# Polarfire SoC register map
Vendor: Microchip; File version: 1.0
CPU: Microchip PolarFire SoC 1.0, little endian
Registers are 32-bit, read-write, reset 0x0 unless marked. A register's access mark holds for its fields unless they carry their own. Offsets are from the block's base; [hi:lo] are bit positions; {n}, {i} and the like mark numbered series; 'fields as' and 'values as' point back to an identical list; <NAME> marks a mode.

## SCB_REGS — SCB_REGS Controller
Base 0x20003000
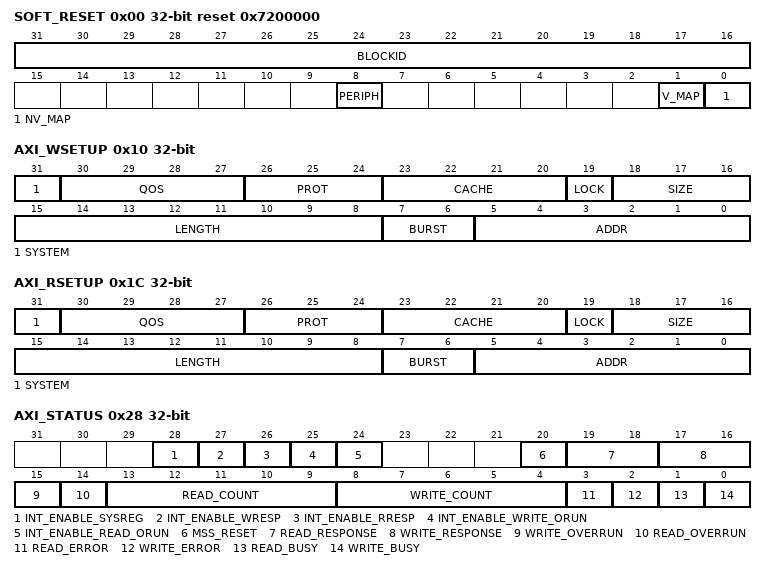
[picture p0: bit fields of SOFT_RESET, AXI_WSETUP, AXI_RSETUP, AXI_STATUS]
0x00 SOFT_RESET reset 0x7200000 — System Reset Register. This MSS soft reset register is not readable or writeable by the MSS or user or DRI.
  [31:16] BLOCKID ro — This returns the block type and chip location.
  [8] PERIPH — This asserts the functional reset of the block. It is asserted at power up, the bit self clears i.e. is similar to a W1P bit. This bit is activated global_periph_reset
  [1] V_MAP — This when asserted resets all the register bits apart from the non-volatile registers, the bit self clears i.e. is similar to a W1P bit. This bit is activated global_map_reset.
  [0] NV_MAP — This when asserted resets all the non-volatile register bits e.g. RW-P bits, the bit self clears i.e. is similar to a W1P bit. This bit is activated global_map_reset.
0x10 AXI_WSETUP — Axi Write Setup. Not accesible from MSS or user or DRI.
  [31] SYSTEM — 0: AXI transaction uses ID 0 and passes through MPU block 1: AXI transaction uses ID 1 and bypasses the MPU block
  [30:27] QOS — Sets the AXI QOS value, higher values have higher priority in the switch
  [26:24] PROT — Sets the AXI protection value
  [23:20] CACHE — Sets the AXI Cache value
  [19] LOCK — Sets the AXI lock
  [18:16] SIZE — Set the AXI size (width)
  [15:8] LENGTH — Sets the AXI burst length
  [7:6] BURST — Sets the AXi burst type
  [5:0] ADDR — Sets the upper 6-bits of the address bus
0x14 AXI_WADDR — AXI Write Address. Not accesible from MSS or user or DRI.
  [31:0] ADDR — This sets the AXI write address. A write to this register triggers the AXI AW cycle
0x18 AXI_WDATA — AXI Write Data. This is write only register, reads will return zero. Not accesible from MSS or user or DRI.
  [31:0] DATA — Write Data, when written will initiate a AHB write transfer through the write data FIFO.Data must be written using word operations. If AWSIZE<=2 then a AXI Write data cycle will be started every cycle, if AWSIZE=3 a AXI Write data cycle will be started every other cycle.
0x1C AXI_RSETUP — AXI Read Setup. Not accesible from MSS or user or DRI.
  fields as AXI_WSETUP
0x20 AXI_RADDR — AXI Read Address. Not accesible from MSS or user or DRI.
  [31:0] ADDR — This sets the AXI read address. A write to this register triggers the AXI AR cycle
0x24 AXI_RDATA — AHB Read data. This is a read only register, writes will be have no effect.
  [31:0] DATA — Read data from the AXI read FIFO
0x28 AXI_STATUS — AXI Master Status. Not accessible from MSS or user or DRI. This register provides status information and writes only supported on bits 28:24
  [28] INT_ENABLE_SYSREG — Enable SCB interrupt from the SCB Interrupt register
  [27] INT_ENABLE_WRESP — Enable SCB interrupt on write response error
  [26] INT_ENABLE_RRESP — Enable SCB interrupt on read response error
  [25] INT_ENABLE_WRITE_ORUN — Enable SCB interrupt on write overrun
  [24] INT_ENABLE_READ_ORUN — Enable SCB interrupt on read overrun
  [20] MSS_RESET — Indicates that the MSS has been reset and the SCB transfer may have failed. Is the internal MSS sticky_reset signal
  [19:18] READ_RESPONSE — Indicates the read response. When a non-zero value is detected the register will hold the value until the read_error bit is cleared or abort asserted
  [17:16] WRITE_RESPONSE — Indicates the write response. When a non-zero value is detected the register will hold the value until the write_error bit is cleared or abort asserted
  [15] WRITE_OVERRUN — Indicates the SCB bus wrote the write FIFO when empty. Is cleared by writing a ‘1’
  [14] READ_OVERRUN — Indicates the SCB bus read the read FIFO when empty. Is cleared by writing a ‘1’
  [13:9] READ_COUNT — Indicates how many 32-bit words are stored in the read FIFO
  [8:4] WRITE_COUNT — Indicates how many 32-bit words are stored in the write FIFO
  [3] READ_ERROR — Set when a read error response is received. Is cleared by writing a ‘1’
  [2] WRITE_ERROR — Set when a write error response is received. Is cleared by writing a ‘1’
  [1] READ_BUSY — Set during arvalid cycle and cleared on the last read response
  [0] WRITE_BUSY — Set during awvalid cycle and cleared on the write response
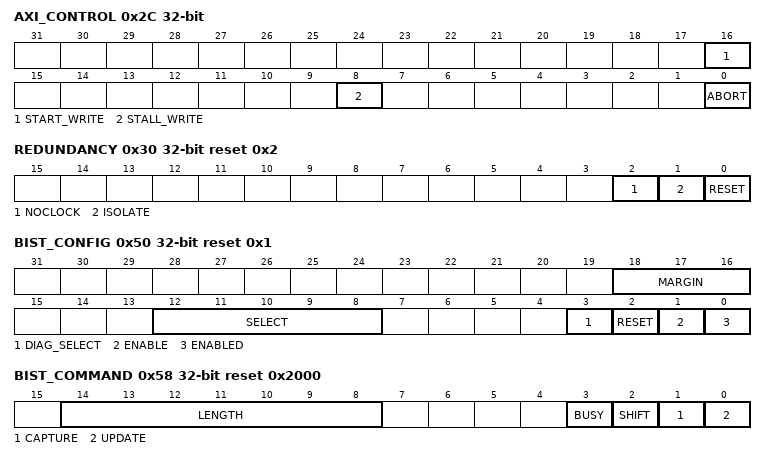
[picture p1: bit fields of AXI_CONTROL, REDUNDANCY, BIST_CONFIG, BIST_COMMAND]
0x2C AXI_CONTROL — AXI Cycle Controls. Not accesible from MSS or user or DRI.
  [16] START_WRITE — Starts AXI transfer when STALL_WRITE is set, reads as zero
  [8] STALL_WRITE — When set prevents the logic initiating AW cycle automatically. Write is started by START_WRITE. Allows up to 16 words (32-bits) of data to be queued allowing AXI to run more efficiently.
  [0] ABORT — Abort current transfer and reset the FSMS. May cause AXI protocol violations
0x30 REDUNDANCY reset 0x2 — Used to program MSS RAM redundancy system during system startup
  [2] NOCLOCK — When set stops the SCB clock creating the Redundancy clock. To allow for large recovery times on the redundancy ISOLATE and RESET inputs this bit should be set prior to toggling the reset/isolate bits and cleared afterwards.
  [1] ISOLATE — Asserts the Redundacy isolate, interface isolated when 1 (can be accessed by MSS in factory mode)
  [0] RESET — Asserts the Redundacy reset (can be accessed by MSS in factory mode)
0x50 BIST_CONFIG reset 0x1 — Used to access the BIST systems
  [18:16] MARGIN — Set the BIST memory margin, factory mode only
  [12:8] SELECT — Select the BIST engine 0-15
  [3] DIAG_SELECT — Assert the DIAG select
  [2] RESET — Assert the BIST reset
  [1] ENABLE — Enable the CPU BIST system
  [0] ENABLED ro — Indicates that CPU may use BIST system, UFS bit may disable this interface, available when factory mode set
0x54 BIST_DATA — Data value to be shifted into BIST system
  [31:0] DATA — Writes sets the data value to shifted, LSB shifted out first. Reads returns the shifted in value, MSB is last bit shifted in.
0x58 BIST_COMMAND reset 0x2000 — BIST Shift Controls
  [14:8] LENGTH — Number of bits to shift 1-127. If set to >32 the outgoing shift data for bits 33 upwards will be zero. This allows MBIST with CSR registers greater than 32 to be started with valid data loaded into bits 23:0 off the CSR register as specified in the data register. When >32 incoming data is not captured in the shift register, if the read data is to extracted then each shift operation should be <=32 bits. To read a 88 bit register will require 3 shift operatiosn of 32, 32 and 24 bits
  [3] BUSY ro — Indicates that the shift is in progress.
  [2] SHIFT — Perform the specified number off shift cycles.
  [1] CAPTURE — Do a shift cycle, may be asserted at the same time as shift, capture is asserted before shift operations start.
  [0] UPDATE — Do an update cycle
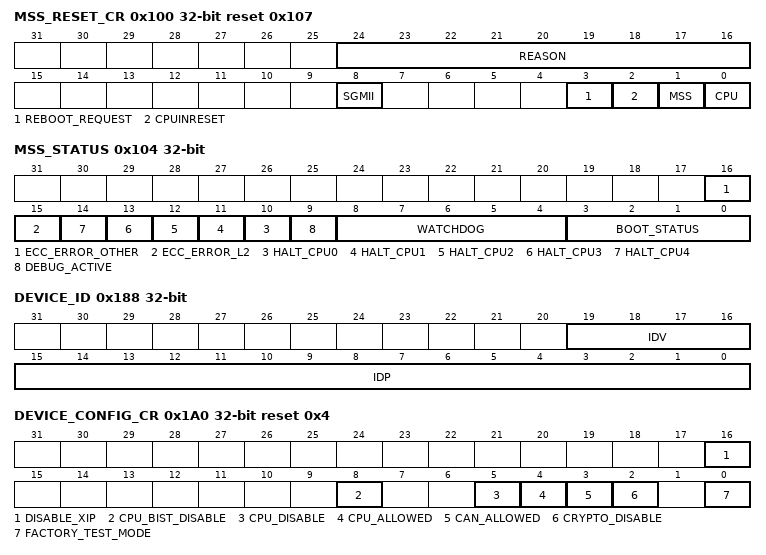
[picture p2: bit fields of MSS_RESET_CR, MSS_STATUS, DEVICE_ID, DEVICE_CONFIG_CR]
0x100 MSS_RESET_CR reset 0x107 — MSS reset Controls
  [24:16] REASON ro — This provides a read off the main SYSREG reset reason register
  [8] SGMII — Asserts a reset the SGMII block containing the MSS reference clock input. Warning that setting this bit causes the external reference clock input to the MSS PLL to disappear. It is advisable to use the SGMII channel soft resets in the PHY instead of this bit. However if E51 software wants to set this bit, the MSS clock source should be switched over to the standby source in advance.
  [3] REBOOT_REQUEST — Reading returns the value of reboot_request. Writing 1 clears the reboot request and the fabric reset enable register
  [2] CPUINRESET ro — Indicates that the CPU's are being help in reset. Will stay active for sixteen CPU clocks after the CPU resets are released
  [1] MSS — Holds the MSS system (i.e. AXI/AHB/APB resets) in reset. When asserted the CPU's are also held in reset. The Trace UDB reset is not asserted by this bit.
  [0] CPU — Holds the CPUS (corplex) in reset.
0x104 MSS_STATUS
  [16] ECC_ERROR_OTHER ro, [15] ECC_ERROR_L2 ro, [n+10] HALT_CPU{n} ro (n=0..4), [9] DEBUG_ACTIVE ro, [8:4] WATCHDOG ro, [3:0] BOOT_STATUS
{0x108+4i} BOOT_ADDR{i} reset 0x20003120 (i=0..4)
  [31:0] ADDRESS — Boot Address i.e. reset vector for the coreplex
0x120 BOOT_ROM0 reset 0x513 — 32-byte ROM for CPU booting Holds eight 32-bit Instructions
  [31:0] DATA — li a0,0
0x124 BOOT_ROM1 reset 0x34451073
  [31:0] DATA — csrw mip,a0
0x128 BOOT_ROM2 reset 0x10500073
  [31:0] DATA — wfi
0x12C BOOT_ROM3 reset 0xFF5FF06F
  [31:0] DATA — j 20003120 <_start>
0x130 BOOT_ROM4 reset 0xFF1FF06F
  [31:0] DATA — j 20003120 <_start>
0x134 BOOT_ROM5 reset 0xFEDFF06F
  [31:0] DATA — j 20003120 <_start>
0x138 BOOT_ROM6 reset 0xFE9FF06F
  [31:0] DATA — j 20003120 <_start>
0x13C BOOT_ROM7 reset 0xFE5FF06F
  [31:0] DATA — j 20003120 <_start>
0x180 FLASH_FREEZE
  [0] IN_PROGRESS — Set by PFC when FF in progress
0x184 PFCIO — Register bit that may drive IOMUX
  [0] IOOUT — Allows PFC to drive an IO pad[4] when IOMUX is configured in MISC mode. This is provided to aid device validation alloing an IO to be easily controlleed by PF-control.
0x188 DEVICE_ID
  [19:16] IDV, [15:0] IDP
0x18C MESSAGE_INT
  [0] ACTIVE — Writing to this bit sets the PFc_message interrupt to the Coreplex, interrupt is cleared by coreplex writing a '0'. It is required that the MSS clears this bit proir to requesting a system service from PFC, on completion PFC will set the MESSAGE register and this bit casuing an interrupt to the MSS indicating the system service is complete.
0x190 MESSAGE
  [31:0] DATA — Data value associated with Message interrupt, used for system service return status
0x194 DEVRST_INT
  [0] ACTIVE — Writing to this bit sets the DEVRST interrupt to the Coreplex via the maintence register, interrupt is cleared by coreplex writing a '0' to this bit
0x198 SCB_INTERRUPT
  [0] ACTIVE — Writing to this bit sets the SCB interrupt signal, interrupt is cleared by PFC writing a '0' to this bit
0x19C MSS_INTERRUPT
  [0] ACTIVE — Writing to this bit sets the MSS to PFC interrupt, interrupt is cleared by PFC writing a '0' to this bit
0x1A0 DEVICE_CONFIG_CR reset 0x4 — This register configures the
  [16] DISABLE_XIP — When set prevents the QSPI module from operating in XIP mode preventinmg direct execution from the QSPI device
  [8] CPU_BIST_DISABLE — When set the CPU's may not initiate MBIST of the RAMS
  [5] CPU_DISABLE — When '1' dissables the SIFIVE CPUs and holds them in reset.
  [4] CPU_ALLOWED — When '1' allows the SIFIVE CPUs to operate. When '0' the CPUS (E51 and U54s) are held in reset. This bit is intended to be set via a factory configuration bit by PF-Control allowing the RiscV cores to be de-featured
  [3] CAN_ALLOWED — When '1' indicates CAN is enabled When '0' the CAN block is held in reset. This bit is intended to be set via a factory configuration bit by PF-Control allowing the CAN core to be de-featured
  [2] CRYPTO_DISABLE — When '1' disables the Crypto block and the Athena block is held in reset. This bit is intended to be set via a factory configuration bit by PF-Control allowing the CAN core to be de-featured
  [0] FACTORY_TEST_MODE — Indicates the device is in manufacturing test mode.
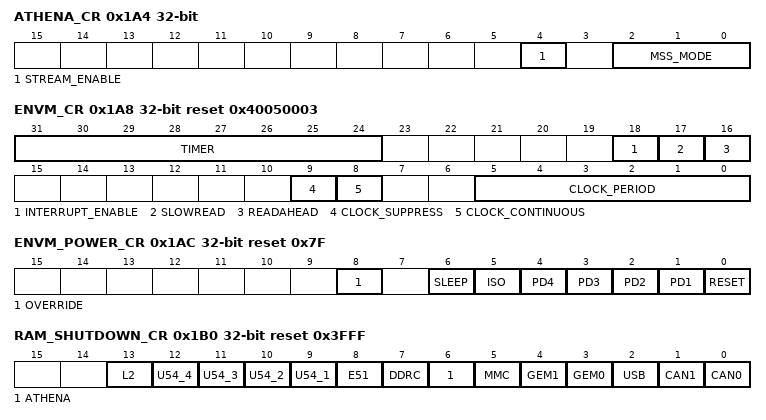
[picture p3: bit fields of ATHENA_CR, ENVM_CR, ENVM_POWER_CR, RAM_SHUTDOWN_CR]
0x1A4 ATHENA_CR — Sets the Athena owners. Not writeable by the MSS or user
  [4] STREAM_ENABLE — Allow Streaming Interface to operate
  [2:0] MSS_MODE — 0xx: Crypto block not available to fabric or MSS 100: Only available to MSS 101: Only avaliable to fabric 110: Available to both, starts with MSS 111: Available to both, starts with fabric If changed during operation then initial change must be to 3'b000.
0x1A8 ENVM_CR reset 0x40050003 — Applies to AHB Controllers when NVM override set
  [31:24] TIMER — Sets the duration of the timer used to detect a non response of slow response from the PNVM on C and R bus accesses. Timer Duration = Value * 4ns. 0x00: Timer dissabled. If the timer expires the AHB cycle is terminates using the HRESP protocol. This field must be set before the PFC override is set and should not be changed whilst it is set.
  [18] INTERRUPT_ENABLE — Enable the PNVM interrupt
  [17] SLOWREAD — When '1' the controller will initate separate PNVM reads for all reads. No buffering or speculative operations will be carried out. When performing word reads incrementing through PNVM each location will be read twice (intended for test use)
  [16] READAHEAD — Enables "readahead" on the PNVM controller. The controller will automatically read the next PNVM location as soon as possible ahead of the AHB request. This will improve read performance when incrementing though memory as the NVM reads and AHB cycles are pipelined. When set non incrementing accesses will take longer as the controller may be in the process of reading the next address and the PNVM cycle needs to complete prior to starting the required read
  [9] CLOCK_SUPPRESS — When set suppresses clock edge between C-Bus access cycles so that they appear as consecutive access cycles.
  [8] CLOCK_CONTINUOUS — When '1' the PNVM clock will be always generated, and not stopped between access cycles. Setting this will increase access latency but mean that the PNVM clock operates at a stable rate.
  [5:0] CLOCK_PERIOD — Sets the number of AHB cycles used to generate the PNVM clock, Clock period = (Value+1) * 4ns (AHB clock at 250MHz) Value must be 1 to 63 (0 defaults to 3) e.g. 9 will generate a 40ns period 25MHz clock if the AHB clock is 250MHz This field must be set before the PFC override is set and should not be changed whilst it is set.
0x1AC ENVM_POWER_CR reset 0x7F — Applies to the eNVM controller
  [8] OVERRIDE — Enable PFC overrides
  [6] SLEEP — Controls the PNVM sleep input
  [5] ISO — Controls the PNVM iso (isolate) input
  [n] PD{n} (n=1..4) — Controls the PNVM pd{n} (powerdown) input
  [0] RESET — Asserts the PNVM reset input (inverted version to PNVM)
0x1B0 RAM_SHUTDOWN_CR reset 0x3FFF — Puts all the RAMS in that block into shut down mode. RAM contents not preserved. Powers down the RAM and periphery circuits. At reset all RAMS powered down
  [13] L2, [n+8] U54_{n} (n=1..4), [8] E51, [7] DDRC, [6] ATHENA, [5] MMC, [4] GEM1, [3] GEM0, [2] USB, [1] CAN1, [0] CAN0
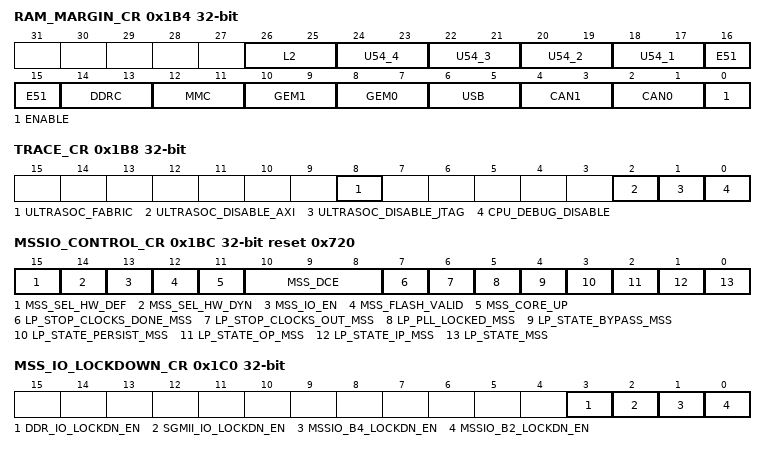
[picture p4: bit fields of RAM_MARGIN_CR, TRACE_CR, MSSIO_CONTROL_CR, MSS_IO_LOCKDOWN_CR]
0x1B4 RAM_MARGIN_CR — Controls the RAM margin inputs on the RAMS. Should not be changeld without explicity guidance from Silicon Engineering
  [26:25] L2, [2n+16:2n+15] U54_{n} (n=1..4), [16:15] E51, [14:13] DDRC, [12:11] MMC, [10:9] GEM1, [8:7] GEM0, [6:5] USB, [4:3] CAN1, [2:1] CAN0, [0] ENABLE
0x1B8 TRACE_CR — Configures the trace and debug connectivity
  [8] ULTRASOC_FABRIC — When set the Utrasoc JTAG interface is connected to fabric EIP connections allowing the JTAG to be directly accessed through fabric IO pins. This also connects the RiscV debugger to the fabric as it passed through the UltraSoc JPAM module
  [2] ULTRASOC_DISABLE_AXI — When set the Utrasoc module is dissabled and will not respond to AXI accesses from PF-Control or the fabric. The JTAG end point will be in bypass mode.
  [1] ULTRASOC_DISABLE_JTAG — When set the Utrasoc module is dissabled and will not respond to JTAG accesses from PF-Control or the fabric. The JTAG end point will be in bypass mode.
  [0] CPU_DEBUG_DISABLE — When set the RiscV debug module is dissabled and will not respond to JTAG accesses from either PF-Control or the fabric. The JTAG end point will be in bypass mode.
0x1BC MSSIO_CONTROL_CR reset 0x720 — Controls the MSS Corner IO control signals
  [15] MSS_SEL_HW_DEF — Sets the value driven out on mss_sel_hw_def_out
  [14] MSS_SEL_HW_DYN — Sets the value driven out on mss_sel_hw_dyn_out
  [13] MSS_IO_EN — Sets the value driven out on mss_io_en (before gating)
  [12] MSS_FLASH_VALID — Sets the value driven out on mss_flash_valid_out
  [11] MSS_CORE_UP — Sets the value driven out on mss_core_up_out
  [10:8] MSS_DCE — Sets the value driven out on mss_dce_out unless PFC asserts its overrides
  [7] LP_STOP_CLOCKS_DONE_MSS ro — Read back of lp_stop_clocks_done input of MSS Corner LP state control
  [6] LP_STOP_CLOCKS_OUT_MSS — Direct control of MSS Corner LP state control
  [5] LP_PLL_LOCKED_MSS — Direct control of MSS Corner LP state control
  [4] LP_STATE_BYPASS_MSS — Direct control of MSS Corner LP state control
  [3] LP_STATE_PERSIST_MSS — Direct control of MSS Corner LP state control
  [2] LP_STATE_OP_MSS — Direct control of MSS Corner LP state control
  [1] LP_STATE_IP_MSS — Direct control of MSS Corner LP state control
  [0] LP_STATE_MSS — Direct control of MSS Corner LP state control (before gating)
0x1C0 MSS_IO_LOCKDOWN_CR ro — Controls the lockdown enable for the MSS-related IO banks
  [3] DDR_IO_LOCKDN_EN — Enable lockdown of DDR-related IO if global lockdown asserted
  [2] SGMII_IO_LOCKDN_EN — Enable lockdown of SGMII-related IO if global lockdown asserted
  [1] MSSIO_B4_LOCKDN_EN — Enable lockdown of MSSIO bank 4 if global lockdown asserted
  [0] MSSIO_B2_LOCKDN_EN — Enable lockdown of MSSIO bank 2 if global lockdown asserted
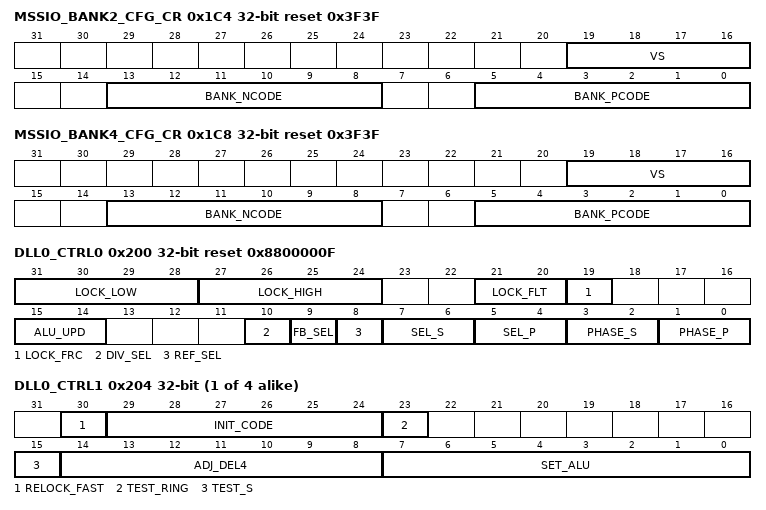
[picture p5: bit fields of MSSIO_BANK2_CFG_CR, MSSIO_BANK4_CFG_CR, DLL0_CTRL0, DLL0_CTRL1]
0x1C4 MSSIO_BANK2_CFG_CR reset 0x3F3F — Configures the MSSIO block
  [19:16] VS — Sets the voltage controls for bank 2
  [13:8] BANK_NCODE — Sets the NCODE value for bank 2
  [5:0] BANK_PCODE — Sets the PCODE value for bank 2
0x1C8 MSSIO_BANK4_CFG_CR reset 0x3F3F — Configures the MSSIO block
  [19:16] VS — Sets the voltage controls for bank 4
  [13:8] BANK_NCODE — Sets the NCODE value for bank 4
  [5:0] BANK_PCODE — Sets the PCODE value for bank 4
0x200 DLL0_CTRL0 reset 0x8800000F — DLL control register 0
  [31:28] LOCK_LOW
  [27:24] LOCK_HIGH
  [21:20] LOCK_FLT
  [19] LOCK_FRC
  [15:14] ALU_UPD
  [10] DIV_SEL
  [9] FB_SEL
  [8] REF_SEL
  [7:6] SEL_S
  [5:4] SEL_P
  [3:2] PHASE_S
  [1:0] PHASE_P — All thes eregisters follow the standard allocation for DLL blocks used in PF. Please refer to the DLL SAC specification for details of register functions.
{0x204+0x20*i} DLL{i}_CTRL1 (i=0..3) — DLL control register 1
  [30] RELOCK_FAST, [29:24] INIT_CODE, [23] TEST_RING, [15] TEST_S, [14:8] ADJ_DEL4, [7:0] SET_ALU
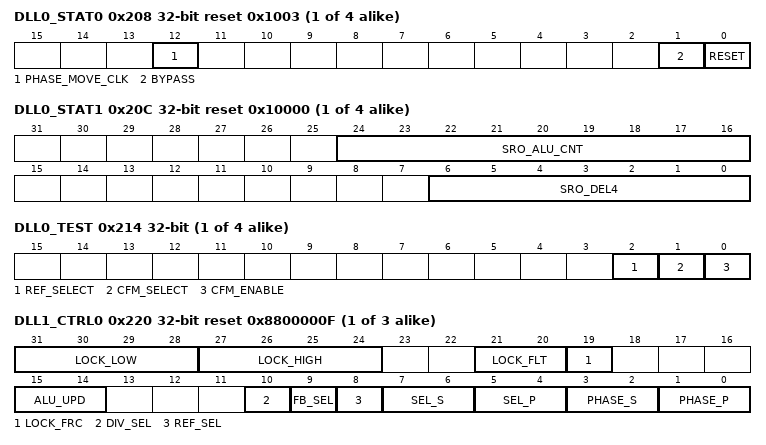
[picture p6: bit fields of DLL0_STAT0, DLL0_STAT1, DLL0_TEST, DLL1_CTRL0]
{0x208+0x20*i} DLL{i}_STAT0 reset 0x1003 (i=0..3) — DLL status register 0
  [12] PHASE_MOVE_CLK, [1] BYPASS, [0] RESET
{0x20C+0x20*i} DLL{i}_STAT1 ro reset 0x10000 (i=0..3) — DLL status register 1
  [24:16] SRO_ALU_CNT, [6:0] SRO_DEL4
{0x210+0x20*i} DLL{i}_STAT2 ro (i=0..3) — DLL status register 2
  [2] SRO_LOCK
{0x214+0x20*i} DLL{i}_TEST (i=0..3) — Enables test modes on the DLL
  [2] REF_SELECT — When '1' the sb clock input is fed to the DLL reference
  [1] CFM_SELECT — Feeds the MBIST clock rather than DLL clock to the CFM block
  [0] CFM_ENABLE — When set enables the DLL output to the frequency meter inside the PF-Controller for test use
{0x200+0x20*i} DLL{i}_CTRL0 reset 0x8800000F (i=1..3) — DLL control register 0
  [31:28] LOCK_LOW
  [27:24] LOCK_HIGH
  [21:20] LOCK_FLT
  [19] LOCK_FRC
  [15:14] ALU_UPD
  [10] DIV_SEL
  [9] FB_SEL
  [8] REF_SEL
  [7:6] SEL_S
  [5:4] SEL_P
  [3:2] PHASE_S
  [1:0] PHASE_P — All these registers follow the standard allocation for DLL blocks used in PF. Please refer to the DLL SAC specification for details of register functions.
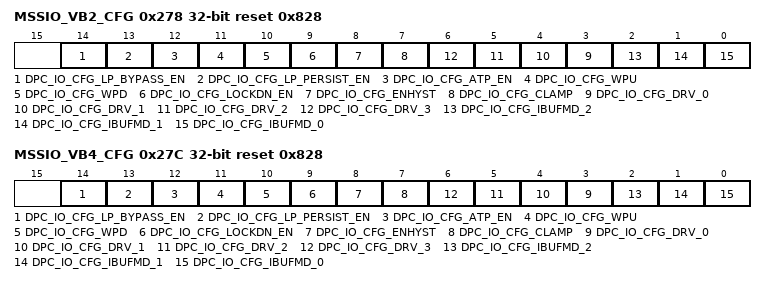
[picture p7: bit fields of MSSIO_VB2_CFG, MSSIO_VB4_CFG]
0x278 MSSIO_VB2_CFG reset 0x828 — dpc values for MSSIO bank 2
  [14] DPC_IO_CFG_LP_BYPASS_EN, [13] DPC_IO_CFG_LP_PERSIST_EN, [12] DPC_IO_CFG_ATP_EN, [11] DPC_IO_CFG_WPU, [10] DPC_IO_CFG_WPD, [9] DPC_IO_CFG_LOCKDN_EN, [8] DPC_IO_CFG_ENHYST, [7] DPC_IO_CFG_CLAMP, [n+3] DPC_IO_CFG_DRV_{n} (n=0..3), [2] DPC_IO_CFG_IBUFMD_2, [1] DPC_IO_CFG_IBUFMD_1, [0] DPC_IO_CFG_IBUFMD_0
0x27C MSSIO_VB4_CFG reset 0x828 — dpc values for MSSIO bank 4
  fields as MSSIO_VB2_CFG
